# SIM3L168_A register map
File version: 1
CPU: 
Registers are 32-bit, read-write, reset 0x0 unless marked. A register's access mark holds for its fields unless they carry their own. Offsets are from the block's base; [hi:lo] are bit positions.

## LCD_0
Base 0x4004D000
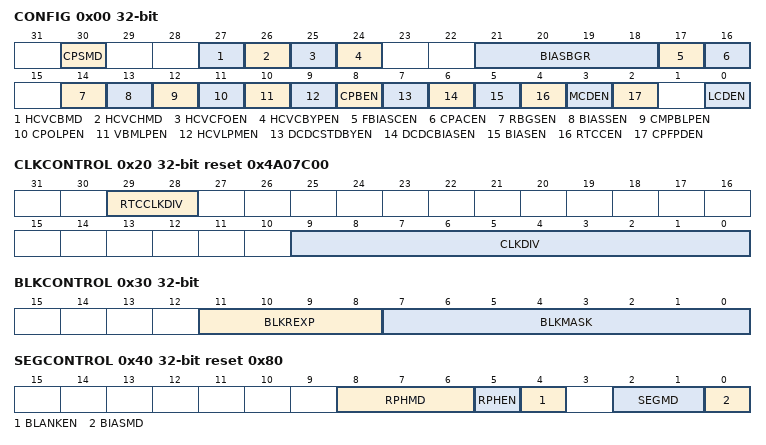
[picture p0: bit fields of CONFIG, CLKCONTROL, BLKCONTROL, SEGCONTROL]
0x00 CONFIG — Configuration
  [30] CPSMD ro — Charge Pump Supply Mode.
    0=EXTERNAL (Select the external supply for the charge pump.); 1=VLCD (Select VLCD as the supply for the charge pump.)
  [27] HCVCBMD — High Contrast Voltage Comparator Bias.
    0=LOW (Set the high contrast voltage comparator to low bias mode.); 1=HIGH (Set the high contrast voltage comparator to high bias mode.)
  [26] HCVCHMD — High Contrast Voltage Comparator Hysteresis.
    0=LOW (Set the high contrast voltage comparator to low hysteresis mode.); 1=HIGH (Set the high contrast voltage comparator to high hysteresis mode.)
  [25] HCVCFOEN — High Contrast Voltage Comparator Force On Enable.
    0=DISABLED (Hardware enables the high contrast voltage comparator as needed.); 1=ENABLED (High contrast voltage comparator force on enabled.)
  [24] HCVCBYPEN — High Contrast Voltage Comparator Bypass Enable.
    0=DISABLED (Hardware enables the high contrast voltage comparator as needed.); 1=ENABLED (High contrast voltage comparator in bypass mode.)
  [21:18] BIASBGR — Bias to Bandgap Switching Cycle Ratio.
  [17] FBIASCEN — Force Bias Continuous Mode Enable.
    0=DISABLED (The bias operates as configured.); 1=ENABLED (Force the bias to operate in continuous mode. The bias will cleanly transition from its configuration settings to continuous mode.)
  [16] CPACEN — Charge Pump Auto-Contrast Enable.
    0=DISABLED (VLCD continues to track VBAT when VBAT drops below the programmed VLCD value.); 1=ENABLED (The module automatically enables the charge pump and maintains the VLCD voltage when VBAT drops below the programmed VBAT monitor level.)
  [14] RBGSEN — Reference Bandgap Switching Enable.
    0=DISABLED (Disable reference bandgap switching mode.); 1=ENABLED (Disable reference bandgap switching mode.)
  [13] BIASSEN — Bias Switching Enable.
    0=DISABLED (Disable bias switching.); 1=ENABLED (Enable bias switching.)
  [12] CMPBLPEN — Comparator Buffer Low Power Enable.
    0=DISABLED (Disable the comparator buffer low power mode.); 1=ENABLED (Enable the comparator buffer low power mode.)
  [11] CPOLPEN — Charge Pump Oscillator Low Power Enable.
    0=DISABLED (Disable the charge pump oscillator low power mode.); 1=ENABLED (Enable the charge pump oscillator low power mode.)
  [10] VBMLPEN — VBAT Monitor Low Power Enable.
    0=DISABLED (Disable the LCD VBAT Monitor low power mode.); 1=ENABLED (Enable the LCD VBAT Monitor low power mode.)
  [9] HCVLPMEN — High Contrast Voltage Low-Power Mode Enable.
    0=DISABLED (Disable the high contrast voltage low-power mode.); 1=ENABLED (Enable the high contrast voltage low-power mode. This mode reduces power consumption whenVLCD is higher than VBAT.)
  [8] CPBEN — Charge Pump Bypass Enable.
    0=DISABLED (The LCD charge pump generates the VLCD voltage.); 1=ENABLED (Bypass the LCD charge pump and connect VLCD directly to VBAT.)
  [7] DCDCSTDBYEN — DCDC Bias Standy Enable.
    0=DISABLED (The DCDC bias is enabled in Power Mode 8.); 1=ENABLED (The DCDC bias is disabled in Power Mode 8.)
  [6] DCDCBIASEN — DCDC Bias Output Enable.
    0=DISABLED (Disable the secondary bias current output.); 1=ENABLED (Enable the secondary bias current output.)
  [5] BIASEN — Bias Enable.
    0=DISABLED (Disable the LCD bias current.); 1=ENABLED (Enable the LCD bias current.)
  [4] RTCCEN — RTC Clock Request Enable.
    0=DISABLED (The LCD module does not require the RTC clock.); 1=ENABLED (The LCD module requires an active and valid RTC clock (RTC0TCLK).)
  [3] MCDEN — LCD Missing Clock Detector Enable.
    0=DISABLED (Disable the dedicated LCD missing clock detector.); 1=ENABLED (Enable the dedicated LCD missing clock detector.)
  [2] CPFPDEN — Charge Pump Full Power Drive Mode Enable.
    0=DISABLED (Disable the LCD charge pump's full power drive mode. The charge pump draws less power but operates with reduced output current capabilities.); 1=ENABLED (Enable the LCD charge pump's full output drive mode. The charge pump operates at full power.)
  [0] LCDEN — Module Enable.
    0=DISABLED (Disable the LCD module.); 1=ENABLED (Enable the LCD module.)
0x20 CLKCONTROL reset 0x4A07C00 — Clock Control
  [29:28] RTCCLKDIV — RTC Input Clock Divider.
    0=DIVIDE_BY_1; 1=DIVIDE_BY_2; 2=DIVIDE_BY_4; 3=DIVIDE_BY_8
  [9:0] CLKDIV — Clock Divider.
0x30 BLKCONTROL — Blinking Control
  [11:8] BLKREXP — Hardware Blinking Rate Divider Exponent.
    2=DIVIDE_BY_2 (Set blink rate divider to divide by 2.); 3=DIVIDE_BY_4 (Set blink rate divider to divide by 4.); 4=DIVIDE_BY_8 (Set blink rate divider to divide by 8.); 5=DIVIDE_BY_16 (Set blink rate divider to divide by 16.); 6=DIVIDE_BY_32 (Set blink rate divider to divide by 32.); 7=DIVIDE_BY_64 (Set blink rate divider to divide by 64.); 8=DIVIDE_BY_128 (Set blink rate divider to divide by 128.); 9=DIVIDE_BY_256 (Set blink rate divider to divide by 256.); 10=DIVIDE_BY_512 (Set blink rate divider to divide by 512.); 11=DIVIDE_BY_1024 (Set blink rate divider to divide by 1024.); 12=DIVIDE_BY_2048 (Set blink rate divider to divide by 2048.); 13=DIVIDE_BY_4096 (Set blink rate divider to divide by 4096.)
  [7:0] BLKMASK — Hardware Blinking Enable.
0x40 SEGCONTROL reset 0x80 — Segment Control
  [8:6] RPHMD — Reset Phase Mode.
  [5] RPHEN — Reset Phase Enable.
    0=DISABLED (Hardware switches the LCD segment and common pin controls directly from one state to another.); 1=ENABLED (Hardware switches the LCD segment and common pin controls to intermediate states for several RTC clock cycles before switching to the next state.)
  [4] BLANKEN — Segment Blank Enable.
    0=DISABLED (Operate segments normally.); 1=ENABLED (Ground the segment pins regardless of the current LCD control state.)
  [2:1] SEGMD — Segment Mode.
    0=STATIC (Select static segment mode with one common COMn.0 used.); 1=2_MUX (Select two-mux segment mode with two commons (COMn.0 and COMn.1) used.); 2=3_MUX (Select three-mux segment mode with three commons (COMn.0, COMn.1, COMn.2) used.); 3=4_MUX (Select four-mux segment mode with four commons (COMn.0, COMn.1, COMn.2 and COMn.3) used.)
  [0] BIASMD — Hardware Bias Mode.
    0=ONE_THIRD (Select 1/3 bias.); 1=ONE_HALF (Select 1/2 bias.)
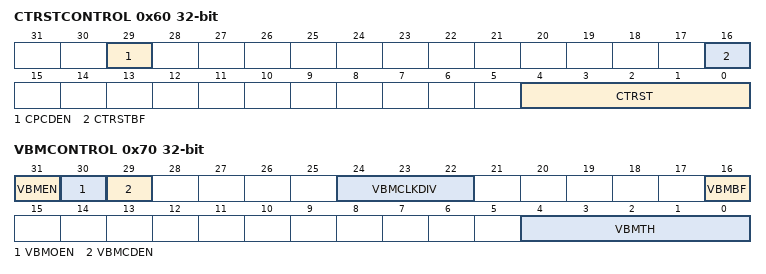
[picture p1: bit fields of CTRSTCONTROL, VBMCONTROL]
0x60 CTRSTCONTROL — Contrast Control
  [29] CPCDEN — Charge Pump Capacitor Divider Enable.
    0=DISABLED (Disable the charge pump capacitor divider.); 1=ENABLED (Enable the charge pump capacitor divider.)
  [16] CTRSTBF ro — Contrast Busy Flag.
    0=NOT_SET (An update of the internal contrast registers is not in progress.); 1=SET (The internal contrast registers are busy updating.)
  [4:0] CTRST — Contrast Voltage.
0x70 VBMCONTROL — VBAT Monitor Control
  [31] VBMEN — VBAT Monitor Enable.
    0=DISABLED (Disable the VBAT monitor.); 1=ENABLED (Enable the VBAT monitor.)
  [30] VBMOEN — VBAT Monitor Offset Enable.
    0=DISABLED (The VBAT monitor threshold set by the VBMTH field functions as an absolute threshold value for the VBAT monitor.); 1=ENABLED (The VBAT monitor threshold set by the VBMTH field functions as an offset to the LCD contrast value set by CTRSTMD.)
  [29] VBMCDEN — VBAT Monitor Capacitor Divider Enable.
    0=DISABLED (Disable the VBAT monitor capacitor divider.); 1=ENABLED (Enable the VBAT monitor capacitor divider.)
  [24:22] VBMCLKDIV — VBAT Monitor Clock Divider.
  [16] VBMBF ro — VBAT Monitor Busy Flag.
    0=NOT_SET (An update of the internal VBAT monitor registers is not in progress.); 1=SET (The internal VBAT monitor registers are busy updating.)
  [4:0] VBMTH — VBAT Monitor Threshold.
0x80 SEGMASK0 — Segment Mask 0
  [31:0] SEGEN — Segment Enable.
0x90 SEGMASK1 — Segment Mask 1
  [7:0] SEGEN — Segment Enable.
0xA0 SEGDATA0 — Segment Data 0
  [31:0] SEGDATA0 — Segment LCDn.0 Control.
0xB0 SEGDATA1 — Segment Data 1
  [31:0] SEGDATA1 — Segment LCDn.8 Control.
0xC0 SEGDATA2 — Segment Data 2
  [31:0] SEGDATA2 — Segment LCDn.16 Control.
0xD0 SEGDATA3 — Segment Data 3
  [31:0] SEGDATA3 — Segment LCDn.24 Control.
0xE0 SEGDATA4 — Segment Data 4
  [31:0] SEGDATA4 — Segment LCDn.32 Control.
